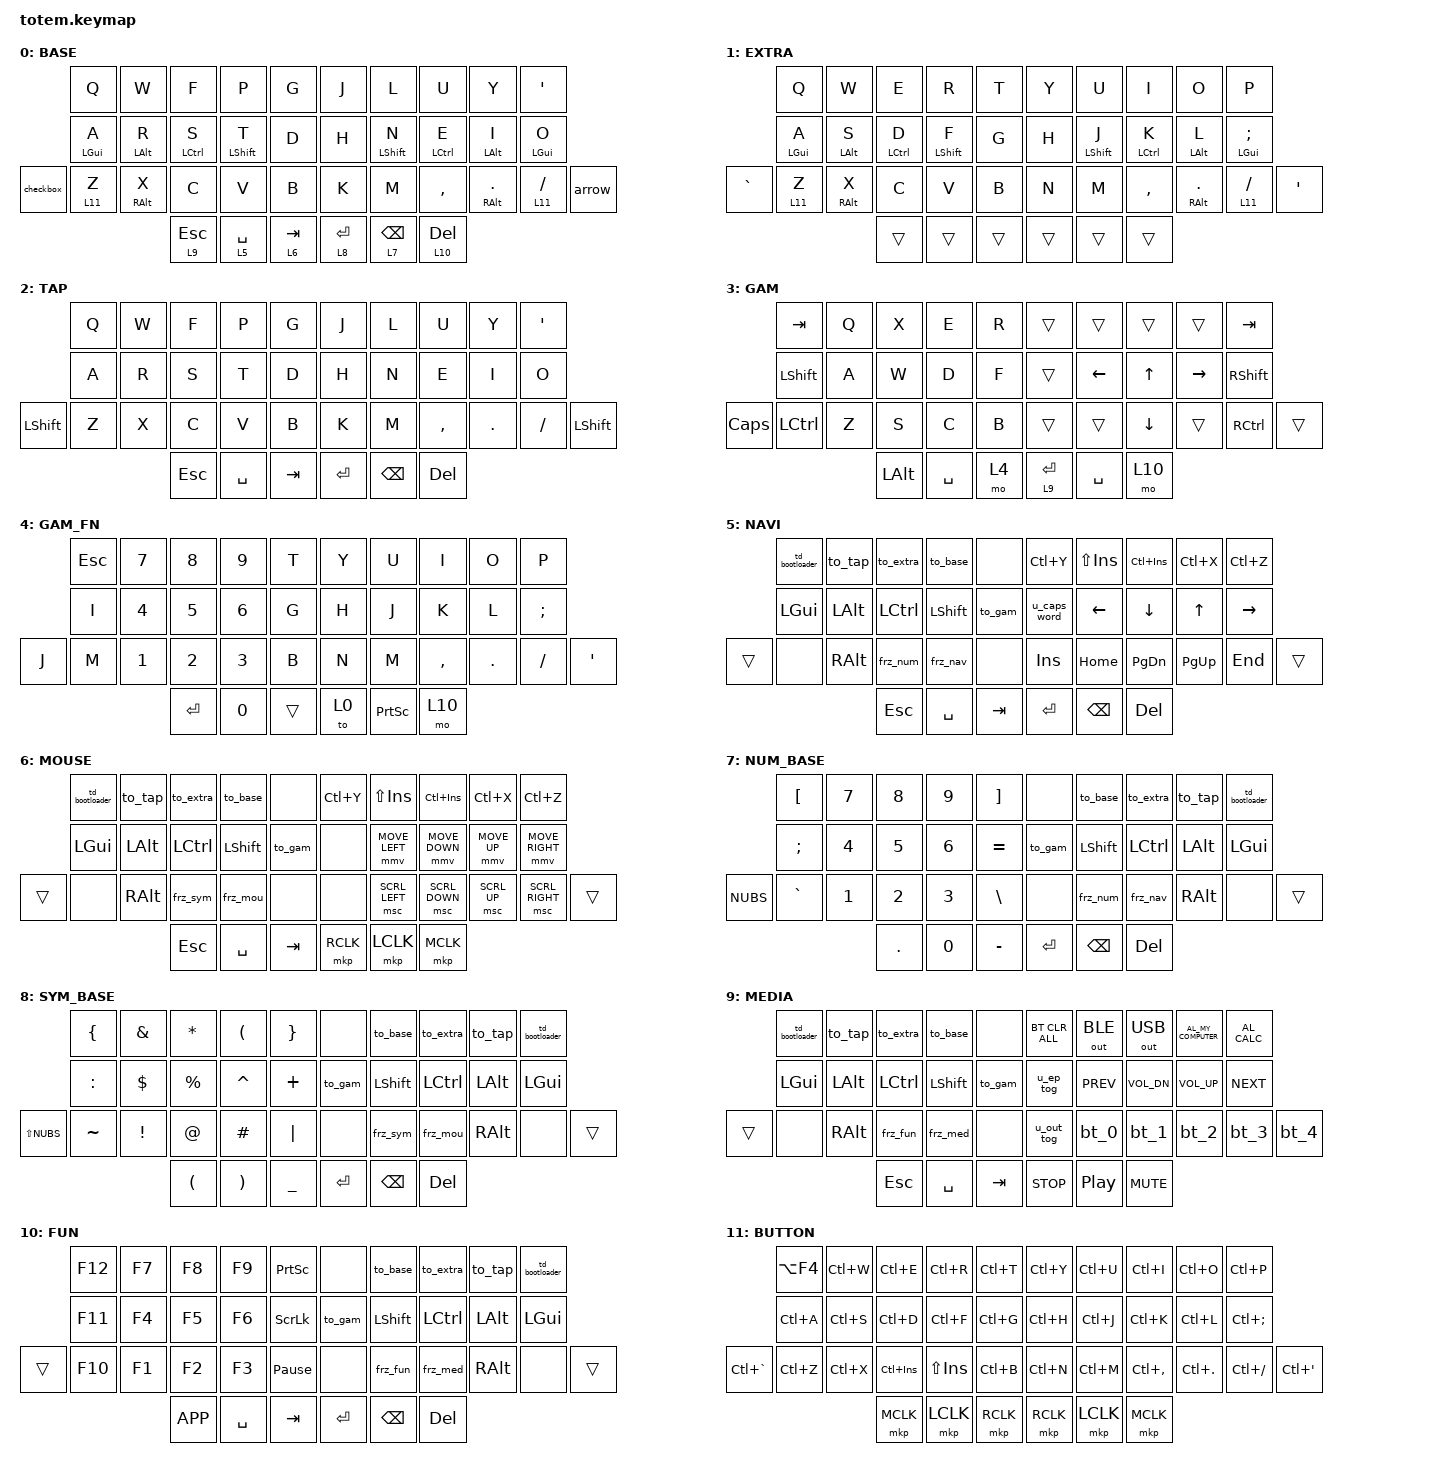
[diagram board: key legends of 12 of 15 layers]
//
//                                                        ▀▀▀▀▀     ▀▀▀▀▀          ▀▀█▀▀
//                                                        ▄▀▀▀▄  ▄  ▄▀▀▀▄  ▄  ▄▀▀▀▄  █  ▄▀▀▀▄
//                                                        █   █  █  █   █  █  █   █  █  █   █
//                                                         ▀▀▀   █   ▀▀▀   █   ▀▀▀   ▀   ▀▀▀
//                                                               █      ▄▄▄█▄▄▄    █   █  
//                                                               ▀      █  █  █     █▄█
//                                                             ▀▀▀▀▀    █  █  █      ▀
//                                                                      ▀  ▀  ▀
//
// ▄▄▄▄▄▄▄▄▄▄▄▄▄▄▄▄▄▄▄▄▄▄▄▄▄▄▄▄▄▄▄▄▄▄▄▄▄▄▄▄▄▄▄▄▄▄▄▄▄▄▄▄▄▄▄▄▄▄▄▄▄▄▄▄▄▄▄▄▄▄▄▄▄▄▄▄▄▄▄▄▄▄▄▄▄▄▄▄▄▄▄▄▄▄▄▄▄▄▄▄▄▄▄▄▄▄▄▄▄▄▄▄▄▄▄▄▄▄▄▄▄▄▄▄▄▄▄▄▄▄▄▄▄▄▄▄▄▄▄▄▄▄▄▄▄▄▄▄▄

#include <behaviors.dtsi>
#include <dt-bindings/zmk/bt.h>
#include <dt-bindings/zmk/ext_power.h>
#include <dt-bindings/zmk/keys.h>
#include <dt-bindings/zmk/outputs.h>
#include <dt-bindings/zmk/pointing.h>

&mt {
    quick-tap-ms = <0>;
    global-quick-tap;
    flavor = "tap-preferred";
    tapping-term-ms = <140>;
};

&lt { tapping-term-ms = <150>; };

/ {
    combos {
        compatible = "zmk,combos";

        un_tap {
            bindings = <&to 0>;
            key-positions = <0 9>;
            layers = <2>;
        };

        extra_kha {
            bindings = <&kp LBKT>;
            key-positions = <6 7>;
            layers = <1>;
        };

        extra_hard_sign {
            bindings = <&kp RBKT>;
            key-positions = <7 8>;
            layers = <1>;
        };

        to_lang_base {
            bindings = <&lang_base>;
            key-positions = <1 3>;
            layers = <0 1>;
        };

        to_lang_extra {
            bindings = <&lang_extra>;
            key-positions = <6 8>;
            layers = <0 1>;
        };
    };

    macros {
        lang_en: lang_en {
            compatible = "zmk,behavior-macro";
            #binding-cells = <0>;
            bindings = <&kp LC(LS(N8))>;
            label = "LANG_EN";
        };

        lang_ru: lang_ru {
            compatible = "zmk,behavior-macro";
            #binding-cells = <0>;
            bindings = <&kp LC(LS(N7))>;
            label = "LANG_RU";
        };

        bt_clear_2: bt_clear_2 {
            compatible = "zmk,behavior-macro";
            #binding-cells = <0>;
            bindings = <&bt BT_SEL 2 &bt BT_CLR>;
            label = "BT_CLEAR_2";
        };

        bt_clear_3: bt_clear_3 {
            compatible = "zmk,behavior-macro";
            #binding-cells = <0>;
            bindings = <&bt BT_SEL 3 &bt BT_CLR>;
            label = "BT_CLEAR_3";
        };

        bt_clear_4: bt_clear_4 {
            compatible = "zmk,behavior-macro";
            #binding-cells = <0>;
            bindings = <&bt BT_SEL 4 &bt BT_CLR>;
            label = "BT_CLEAR_4";
        };

        bt_clear_0: bt_clear_0 {
            compatible = "zmk,behavior-macro";
            #binding-cells = <0>;
            bindings = <&bt BT_SEL 0 &bt BT_CLR>;
            label = "BT_CLEAR_0";
        };

        bt_clear_1: bt_clear_1 {
            compatible = "zmk,behavior-macro";
            #binding-cells = <0>;
            bindings = <&bt BT_SEL 1 &bt BT_CLR>;
            label = "BT_CLEAR_1";
        };

        ml: ml {
            compatible = "zmk,behavior-macro-one-param";
            #binding-cells = <1>;
            bindings =
                <&macro_param_1to1 &key_on MACRO_PLACEHOLDER &layer_on 14>,
                <&macro_pause_for_release>,
                <&macro_param_1to1 &key_off MACRO_PLACEHOLDER &layer_off 14>;

            label = "ML";
            wait-ms = <0>;
            tap-ms = <0>;
        };

        lang_base: lang_base {
            compatible = "zmk,behavior-macro";
            #binding-cells = <0>;
            bindings = <&lang_en &to 0>;
            label = "LANG_BASE";
        };

        lang_extra: lang_extra {
            compatible = "zmk,behavior-macro";
            #binding-cells = <0>;
            bindings = <&lang_ru &to 1>;
            label = "LANG_EXTRA";
        };

        checkbox: checkbox {
            compatible = "zmk,behavior-macro";
            #binding-cells = <0>;
            bindings = <&kp HOME &kp MINUS &kp SPACE &kp LBKT &kp SPACE &kp RBKT &kp SPACE &kp END>;
            label = "CHECKBOX";
        };

        arrow: arrow {
            compatible = "zmk,behavior-macro";
            #binding-cells = <0>;
            bindings = <&kp MINUS &kp GT>;
            label = "ARROW";
        };
    };

    behaviors {
        td_bootloader: td_bootloader {
            compatible = "zmk,behavior-tap-dance";
            label = "TD_BOOTLOADER";
            #binding-cells = <0>;
            bindings = <&none>, <&bootloader>;
        };

        bt_0: bt_0 {
            compatible = "zmk,behavior-mod-morph";
            label = "BT_0";
            bindings = <&bt BT_SEL 0>, <&bt_clear_0>;

            #binding-cells = <0>;
            mods = <(MOD_LSFT)>;
        };

        bt_1: bt_1 {
            compatible = "zmk,behavior-mod-morph";
            label = "BT_1";
            bindings = <&bt BT_SEL 1>, <&bt_clear_1>;

            #binding-cells = <0>;
            mods = <(MOD_LSFT)>;
        };

        bt_2: bt_2 {
            compatible = "zmk,behavior-mod-morph";
            label = "BT_2";
            bindings = <&bt BT_SEL 2>, <&bt_clear_2>;

            #binding-cells = <0>;
            mods = <(MOD_LSFT)>;
        };

        bt_3: bt_3 {
            compatible = "zmk,behavior-mod-morph";
            label = "BT_3";
            bindings = <&bt BT_SEL 3>, <&bt_clear_3>;

            #binding-cells = <0>;
            mods = <(MOD_LSFT)>;
        };

        bt_4: bt_4 {
            compatible = "zmk,behavior-mod-morph";
            label = "BT_4";
            bindings = <&bt BT_SEL 4>, <&bt_clear_4>;

            #binding-cells = <0>;
            mods = <(MOD_LSFT)>;
        };

        u_out_tog: u_out_tog {
            compatible = "zmk,behavior-mod-morph";
            label = "U_OUT_TOG";
            bindings = <&out OUT_TOG>, <&out OUT_USB>;

            #binding-cells = <0>;
            mods = <(MOD_LSFT)>;
        };

        u_ep_tog: u_ep_tog {
            compatible = "zmk,behavior-mod-morph";
            label = "U_EP_TOG";
            bindings = <&ext_power EP_TOG>, <&ext_power EP_OFF>;

            #binding-cells = <0>;
            mods = <(MOD_LSFT)>;
        };

        u_caps_word: u_caps_word {
            compatible = "zmk,behavior-mod-morph";
            label = "U_CAPS_WORD";
            bindings = <&caps_word>, <&kp CAPS>;

            #binding-cells = <0>;
            mods = <(MOD_LSFT)>;
        };

        to_extra: to_extra {
            compatible = "zmk,behavior-tap-dance";
            label = "TO_EXTRA";
            #binding-cells = <0>;
            bindings = <&none>, <&to 1>;
        };

        to_tap: to_tap {
            compatible = "zmk,behavior-tap-dance";
            label = "TO_TAP";
            #binding-cells = <0>;
            bindings = <&none>, <&to 2>;
        };

        to_base: to_base {
            compatible = "zmk,behavior-tap-dance";
            label = "TO_BASE";
            #binding-cells = <0>;
            bindings = <&none>, <&to 0>;
        };

        to_gam: to_gam {
            compatible = "zmk,behavior-tap-dance";
            label = "TO_GAM";
            #binding-cells = <0>;
            bindings = <&none>, <&to 3>;
        };

        frz_nav: frz_nav {
            compatible = "zmk,behavior-tap-dance";
            label = "FRZ_NAV";
            #binding-cells = <0>;
            bindings = <&none>, <&to 5>;
        };

        frz_mou: frz_mou {
            compatible = "zmk,behavior-tap-dance";
            label = "FRZ_MOU";
            #binding-cells = <0>;
            bindings = <&none>, <&to 6>;
        };

        frz_med: frz_med {
            compatible = "zmk,behavior-tap-dance";
            label = "FRZ_MED";
            #binding-cells = <0>;
            bindings = <&none>, <&to 9>;
        };

        frz_num: frz_num {
            compatible = "zmk,behavior-tap-dance";
            label = "FRZ_NUM";
            #binding-cells = <0>;
            bindings = <&none>, <&to 7>;
        };

        frz_sym: frz_sym {
            compatible = "zmk,behavior-tap-dance";
            label = "FRZ_SYM";
            #binding-cells = <0>;
            bindings = <&none>, <&to 8>;
        };

        frz_fun: frz_fun {
            compatible = "zmk,behavior-tap-dance";
            label = "FRZ_FUN";
            #binding-cells = <0>;
            bindings = <&none>, <&to 10>;
        };

        mt_pinky: mt_pinky {
            compatible = "zmk,behavior-hold-tap";
            label = "MT_PINKY";
            bindings = <&kp>, <&kp>;

            #binding-cells = <2>;
            quick-tap-ms = <0>;
            tapping-term-ms = <150>;
            flavor = "tap-preferred";
        };

        mt_index: mt_index {
            compatible = "zmk,behavior-hold-tap";
            label = "MT_INDEX";
            bindings = <&kp>, <&kp>;

            #binding-cells = <2>;
            flavor = "balanced";
            tapping-term-ms = <100>;
            quick-tap-ms = <0>;
        };

        key_on: key_on {
            compatible = "zmk,behavior-key-toggle";
            label = "KEY_ON";
            #binding-cells = <1>;
        };

        key_off: key_off {
            compatible = "zmk,behavior-key-toggle";
            label = "KEY_OFF";
            #binding-cells = <1>;
            toggle-mode = "off";
        };

        layer_on: layer_on {
            compatible = "zmk,behavior-toggle-layer";
            label = "LAYER_ON";
            #binding-cells = <1>;
        };

        layer_off: layer_off {
            compatible = "zmk,behavior-toggle-layer";
            label = "LAYER_OFF";
            #binding-cells = <1>;
            toggle-mode = "off";
        };

        hrml: hrml {
            compatible = "zmk,behavior-hold-tap";
            label = "HRML";
            bindings = <&ml>, <&kp>;

            #binding-cells = <2>;
            tapping-term-ms = <140>;
            quick-tap-ms = <0>;
            flavor = "tap-preferred";
        };

        hrml_pinky: hrml_pinky {
            compatible = "zmk,behavior-hold-tap";
            label = "HRML_PINKY";
            bindings = <&ml>, <&kp>;

            #binding-cells = <2>;
            tapping-term-ms = <150>;
            quick-tap-ms = <0>;
            flavor = "tap-preferred";
        };
    };

    keymap {
        compatible = "zmk,keymap";

        base_layer {
            label = "BASE";
            bindings = <
           &kp Q             &kp W       &kp F        &kp P              &kp G        &kp J      &kp L              &kp U        &kp Y         &kp SQT
           &mt_pinky LGUI A  &mt LALT R  &mt LCTRL S  &mt_index LSHFT T  &kp D        &kp H      &mt_index LSHFT N  &mt LCTRL E  &mt LALT I    &mt_pinky LGUI O
&checkbox  &lt 11 Z          &mt RALT X  &kp C        &kp V              &kp B        &kp K      &kp M              &kp COMMA    &mt RALT DOT  &lt 11 FSLH       &arrow
                                         &lt 9 ESC    &lt 5 SPACE        &lt 6 TAB    &lt 8 RET  &lt 7 BSPC         &lt 10 DEL
            >;
        };

        extra_layer {
            label = "EXTRA";
            bindings = <
           &kp Q               &kp W         &kp E          &kp R              &kp T     &kp Y   &kp U              &kp I          &kp O           &kp P
           &hrml_pinky LGUI A  &hrml LALT S  &hrml LCTRL D  &mt_index LSHFT F  &kp G     &kp H   &mt_index LSHFT J  &hrml LCTRL K  &hrml LALT L    &hrml_pinky LGUI SEMI
&kp GRAVE  &lt 11 Z            &hrml RALT X  &kp C          &kp V              &kp B     &kp N   &kp M              &kp COMMA      &hrml RALT DOT  &lt 11 FSLH            &kp SQT
                                             &trans         &trans             &trans    &trans  &trans             &trans
            >;
        };

        tap_layer {
            label = "TAP";
            bindings = <
           &kp Q  &kp W  &kp F    &kp P      &kp G      &kp J      &kp L     &kp U      &kp Y    &kp SQT
           &kp A  &kp R  &kp S    &kp T      &kp D      &kp H      &kp N     &kp E      &kp I    &kp O
&kp LSHFT  &kp Z  &kp X  &kp C    &kp V      &kp B      &kp K      &kp M     &kp COMMA  &kp DOT  &kp FSLH  &kp LSHFT
                         &kp ESC  &kp SPACE  &kp TAB    &kp ENTER  &kp BSPC  &kp DEL
            >;
        };

        gaming_layer {
            bindings = <
          &kp TAB    &kp Q  &kp X     &kp E      &kp R    &trans     &trans     &trans    &trans     &kp TAB
          &kp LSHFT  &kp A  &kp W     &kp D      &kp F    &trans     &kp LEFT   &kp UP    &kp RIGHT  &kp RSHFT
&kp CAPS  &kp LCTRL  &kp Z  &kp S     &kp C      &kp B    &trans     &trans     &kp DOWN  &trans     &kp RCTRL  &trans
                            &kp LALT  &kp SPACE  &mo 4    &lt 9 RET  &kp SPACE  &mo 10
            >;

            label = "GAM";
        };

        gaming_fn {
            bindings = <
       &kp ESC  &kp N7  &kp N8   &kp N9  &kp T     &kp Y  &kp U      &kp I      &kp O    &kp P
       &kp I    &kp N4  &kp N5   &kp N6  &kp G     &kp H  &kp J      &kp K      &kp L    &kp SEMI
&kp J  &kp M    &kp N1  &kp N2   &kp N3  &kp B     &kp N  &kp M      &kp COMMA  &kp DOT  &kp FSLH  &kp SQT
                        &kp RET  &kp N0  &trans    &to 0  &kp PSCRN  &mo 10
            >;

            label = "GAM_FN";
        };

        navi {
            bindings = <
        &td_bootloader  &to_tap   &to_extra  &to_base   &none      &kp LC(Y)     &kp LS(INS)  &kp LC(INS)  &kp LC(X)  &kp LC(Z)
        &kp LGUI        &kp LALT  &kp LCTRL  &kp LSHFT  &to_gam    &u_caps_word  &kp LEFT     &kp DOWN     &kp UP     &kp RIGHT
&trans  &none           &kp RALT  &frz_num   &frz_nav   &none      &kp INS       &kp HOME     &kp PG_DN    &kp PG_UP  &kp END    &trans
                                  &kp ESC    &kp SPACE  &kp TAB    &kp RET       &kp BSPC     &kp DEL
            >;

            label = "NAVI";
        };

        mouse {
            bindings = <
        &td_bootloader  &to_tap   &to_extra  &to_base   &none      &kp LC(Y)  &kp LS(INS)     &kp LC(INS)     &kp LC(X)     &kp LC(Z)
        &kp LGUI        &kp LALT  &kp LCTRL  &kp LSHFT  &to_gam    &none      &mmv MOVE_LEFT  &mmv MOVE_DOWN  &mmv MOVE_UP  &mmv MOVE_RIGHT
&trans  &none           &kp RALT  &frz_sym   &frz_mou   &none      &none      &msc SCRL_LEFT  &msc SCRL_DOWN  &msc SCRL_UP  &msc SCRL_RIGHT  &trans
                                  &kp ESC    &kp SPACE  &kp TAB    &mkp RCLK  &mkp LCLK       &mkp MCLK
            >;

            label = "MOUSE";
        };

        num_base {
            bindings = <
          &kp LBKT   &kp N7  &kp N8   &kp N9  &kp RBKT     &none      &to_base   &to_extra  &to_tap   &td_bootloader
          &kp SEMI   &kp N4  &kp N5   &kp N6  &kp EQUAL    &to_gam    &kp LSHFT  &kp LCTRL  &kp LALT  &kp LGUI
&kp NUBS  &kp GRAVE  &kp N1  &kp N2   &kp N3  &kp BSLH     &none      &frz_num   &frz_nav   &kp RALT  &none           &trans
                             &kp DOT  &kp N0  &kp MINUS    &kp ENTER  &kp BSPC   &kp DEL
            >;

            label = "NUM_BASE";
        };

        sym_base {
            bindings = <
              &kp LEFT_BRACE  &kp AMPS  &kp STAR   &kp LPAR   &kp RBRC     &none      &to_base   &to_extra  &to_tap   &td_bootloader
              &kp COLON       &kp DLLR  &kp PRCNT  &kp CARET  &kp PLUS     &to_gam    &kp LSHFT  &kp LCTRL  &kp LALT  &kp LGUI
&kp LS(NUBS)  &kp TILDE       &kp EXCL  &kp AT     &kp HASH   &kp PIPE     &none      &frz_sym   &frz_mou   &kp RALT  &none           &trans
                                        &kp LPAR   &kp RPAR   &kp UNDER    &kp ENTER  &kp BSPC   &kp DEL
            >;

            label = "SYM_BASE";
        };

        media {
            bindings = <
        &td_bootloader  &to_tap   &to_extra  &to_base   &none      &bt BT_CLR_ALL  &out OUT_BLE  &out OUT_USB  &kp C_AL_MY_COMPUTER  &kp C_AL_CALC
        &kp LGUI        &kp LALT  &kp LCTRL  &kp LSHFT  &to_gam    &u_ep_tog       &kp C_PREV    &kp C_VOL_DN  &kp C_VOL_UP          &kp C_NEXT
&trans  &none           &kp RALT  &frz_fun   &frz_med   &none      &u_out_tog      &bt_0         &bt_1         &bt_2                 &bt_3          &bt_4
                                  &kp ESC    &kp SPACE  &kp TAB    &kp C_STOP      &kp C_PP      &kp K_MUTE
            >;

            label = "MEDIA";
        };

        fun {
            bindings = <
        &kp F12  &kp F7  &kp F8     &kp F9     &kp PSCRN          &none      &to_base   &to_extra  &to_tap   &td_bootloader
        &kp F11  &kp F4  &kp F5     &kp F6     &kp SCROLLLOCK     &to_gam    &kp LSHFT  &kp LCTRL  &kp LALT  &kp LGUI
&trans  &kp F10  &kp F1  &kp F2     &kp F3     &kp PAUSE_BREAK    &none      &frz_fun   &frz_med   &kp RALT  &none           &trans
                         &kp K_APP  &kp SPACE  &kp TAB            &kp ENTER  &kp BSPC   &kp DEL
            >;

            label = "FUN";
        };

        button {
            bindings = <
               &kp LA(F4)  &kp LC(W)  &kp LC(E)    &kp LC(R)    &kp LC(T)    &kp LC(Y)  &kp LC(U)  &kp LC(I)      &kp LC(O)    &kp LC(P)
               &kp LC(A)   &kp LC(S)  &kp LC(D)    &kp LC(F)    &kp LC(G)    &kp LC(H)  &kp LC(J)  &kp LC(K)      &kp LC(L)    &kp LC(SEMI)
&kp LC(GRAVE)  &kp LC(Z)   &kp LC(X)  &kp LC(INS)  &kp LS(INS)  &kp LC(B)    &kp LC(N)  &kp LC(M)  &kp LC(COMMA)  &kp LC(DOT)  &kp LC(FSLH)  &kp LC(SQT)
                                      &mkp MCLK    &mkp LCLK    &mkp RCLK    &mkp RCLK  &mkp LCLK  &mkp MCLK
            >;

            label = "BUTTON";
        };

        num_extra {
            bindings = <
        &trans   &trans  &trans  &trans  &trans    &trans  &trans  &trans  &trans  &trans
        &kp SQT  &trans  &trans  &trans  &trans    &trans  &trans  &trans  &trans  &trans
&trans  &trans   &trans  &trans  &trans  &trans    &trans  &trans  &trans  &trans  &trans  &trans
                         &trans  &trans  &trans    &trans  &trans  &trans
            >;

            label = "NUM_EXTRA";
        };

        sym_extra {
            bindings = <
        &trans   &trans  &trans  &trans  &trans    &trans  &trans  &trans  &trans  &trans
        &kp DQT  &trans  &trans  &trans  &trans    &trans  &trans  &trans  &trans  &trans
&trans  &trans   &trans  &trans  &trans  &trans    &trans  &trans  &trans  &trans  &trans  &trans
                         &trans  &trans  &trans    &trans  &trans  &trans
            >;

            label = "SYM_EXTRA";
        };

        hrm_shortcuts {
            bindings = <
        &kp Q             &kp W       &kp F        &kp P               &kp G     &kp J   &kp L              &kp U        &kp Y         &kp APOS
        &mt_pinky LGUI A  &mt LALT R  &mt LCTRL S  &mt_index LSHIFT T  &kp D     &kp H   &mt_index LSHFT N  &mt LCTRL E  &mt LALT I    &mt_pinky LGUI O
&trans  &kp Z             &mt RALT X  &kp C        &kp V               &kp B     &kp K   &kp M              &kp COMMA    &mt RALT DOT  &kp FSLH          &trans
                                      &trans       &trans              &trans    &trans  &trans             &trans
            >;

            label = "HRM_SHORT";
        };
    };

    conditional_layers {
        compatible = "zmk,conditional-layers";

        num_for_extra {
            if-layers = <1 7>;
            then-layer = <12>;
        };

        sym_for_extra {
            if-layers = <1 8>;
            then-layer = <13>;
        };
    };
};
